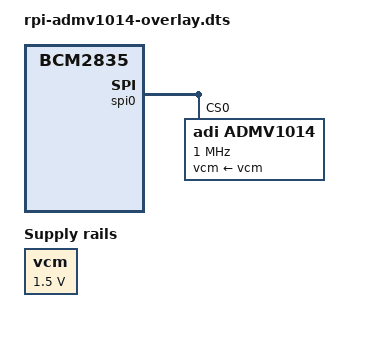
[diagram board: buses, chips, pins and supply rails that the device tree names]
// SPDX-License-Identifier: GPL-2.0
/dts-v1/;
/plugin/;

/ {
	compatible = "brcm,bcm2835";

	fragment@0 {
		target = <&spidev0>;

		__overlay__ {
			status = "disabled";
		};
	};

	fragment@1 {
		target-path = "/";
		__overlay__ {
			clocks {
				admv1014_lo: clock@0 {
					compatible = "fixed-clock";

					clock-frequency = <1000000000>;
					clock-output-names = "lo_in";
					#clock-cells = <0>;
				};
			};
		};
	};

	fragment@2 {
		target-path = "/";
		__overlay__ {
			vcm: fixedregulator@0 {
				compatible = "regulator-fixed";
				regulator-name = "vcm";
				regulator-min-microvolt = <1500000>;
				regulator-max-microvolt = <1500000>;
				regulator-boot-on;
			};
		};
	};

	fragment@3 {
		target = <&spi0>;

		__overlay__{
			#address-cells = <1>;
			#size-cells = <0>;
			status = "okay";

			admv1014@0{
				compatible = "adi,admv1014";
				reg = <0>;
				spi-max-frequency = <1000000>;
				clocks = <&admv1014_lo>;
				clock-names = "lo_in";
				clock-scales = <1 8>;
				vcm-supply = <&vcm>;
				adi,quad-se-mode = <0>;
				adi,parity-en;
				adi,p1db-comp = <3>;
				adi,det-prog = <4>;
				adi,bb-amp-gain-ctrl = <0>;
			};
		};
	};
};
